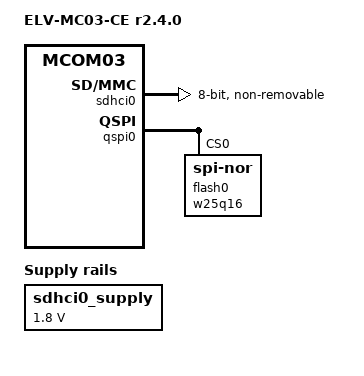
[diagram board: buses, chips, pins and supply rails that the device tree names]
// SPDX-License-Identifier: GPL-2.0+
/*
 * Copyright 2023 RnD Center "ELVEES", JSC
 */

/dts-v1/;

#include <dt-bindings/gpio/gpio.h>

#include "mcom03.dtsi"

/ {
	model = "ELV-MC03-CE r2.4.0";
	compatible = "elvees,elvmc03ce-r2.4.0",
		     "elvees,elvmc03ce",
		     "elvees,mcom03";

	sdhci0_supply: regulator@0 {
		compatible = "regulator-fixed";
		regulator-name = "sdhci0-supply";
		regulator-min-microvolt = <1800000>;
		regulator-max-microvolt = <1800000>;
		regulator-always-on;
	};
};

/* Connected to eMMC */
&sdhci0 {
	status = "okay";

	non-removable;
	bus-width = <8>;

	vqmmc-supply = <&sdhci0_supply>;
};

&qspi0 {
	status = "okay";

	flash0: w25q16@0 {
		#address-cells = <1>;
		#size-cells = <1>;
		compatible = "jedec,spi-nor", "spi-flash";
		reg = <0x0>;

		spi-tx-bus-width = <4>;
		spi-rx-bus-width = <4>;
	};
};

ser1: &uart0 { };
